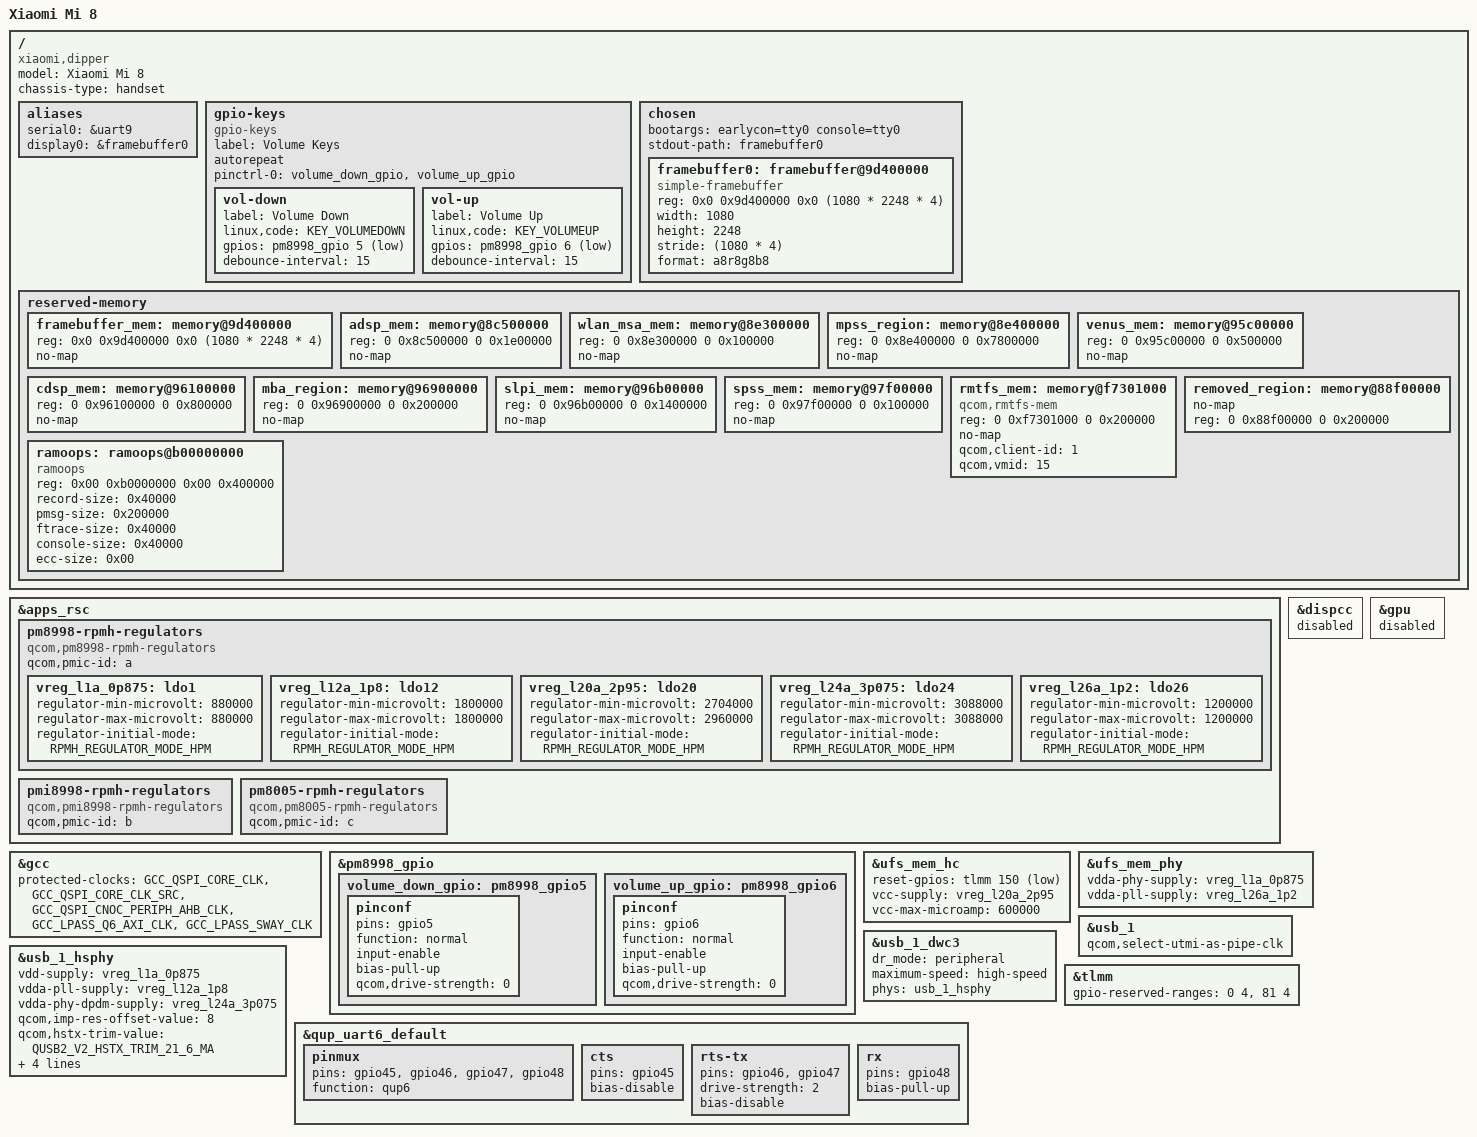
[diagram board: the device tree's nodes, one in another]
// SPDX-License-Identifier: GPL-2.0
/*
 * Copyright (c) 2022, Eralp Çelebi <eralp.celebi.personal@gmail.com>
 *
 */

/dts-v1/;

#include <dt-bindings/input/linux-event-codes.h>
#include <dt-bindings/interrupt-controller/irq.h>
#include <dt-bindings/regulator/qcom,rpmh-regulator.h>
#include <dt-bindings/sound/qcom,q6afe.h>
#include <dt-bindings/sound/qcom,q6asm.h>
#include <dt-bindings/sound/qcom,q6voice.h>

#include "sdm845.dtsi"
#include "pm8998.dtsi"
#include "pmi8998.dtsi"

/*
 * Delete following upstream (sdm845.dtsi) reserved
 * memory mappings which are different in this device.
 */
/delete-node/ &tz_mem;
/delete-node/ &adsp_mem;
/delete-node/ &wlan_msa_mem;
/delete-node/ &mpss_region;
/delete-node/ &venus_mem;
/delete-node/ &cdsp_mem;
/delete-node/ &mba_region;
/delete-node/ &slpi_mem;
/delete-node/ &spss_mem;
/delete-node/ &rmtfs_mem;

/ {
    model = "Xiaomi Mi 8";
    compatible = "xiaomi,dipper", "qcom,sdm845";
    chassis-type = "handset";

    aliases {
		serial0 = &uart9;
		display0 = &framebuffer0;
	};

	gpio-keys {
		compatible = "gpio-keys";
		label = "Volume Keys";
		autorepeat;

		pinctrl-names = "default";
		pinctrl-0 = <&volume_down_gpio &volume_up_gpio>;

		vol-down {
			label = "Volume Down";
			linux,code = <KEY_VOLUMEDOWN>;
			gpios = <&pm8998_gpio 5 GPIO_ACTIVE_LOW>;
			debounce-interval = <15>;
		};

		vol-up {
			label = "Volume Up";
			linux,code = <KEY_VOLUMEUP>;
			gpios = <&pm8998_gpio 6 GPIO_ACTIVE_LOW>;
			debounce-interval = <15>;
		};
	};

    chosen {
        bootargs = "earlycon=tty0 console=tty0";

		#address-cells = <2>;
		#size-cells = <2>;
		ranges;

		stdout-path = "framebuffer0";

        framebuffer0: framebuffer@9d400000 {
            compatible = "simple-framebuffer";
			reg = <0x0 0x9d400000 0x0 (1080 * 2248 * 4)>;
			width = <1080>;
			height = <2248>;
			stride = <(1080 * 4)>;
			format = "a8r8g8b8";
        };
    };

    reserved-memory {
        ranges;

        framebuffer_mem: memory@9d400000 {
			reg = <0x0 0x9d400000 0x0 (1080 * 2248 * 4)>;
			no-map;
		};

		adsp_mem: memory@8c500000 {
			reg = <0 0x8c500000 0 0x1e00000>;
			no-map;
		};

		wlan_msa_mem: memory@8e300000 {
			reg = <0 0x8e300000 0 0x100000>;
			no-map;
		};

		mpss_region: memory@8e400000 {
			reg = <0 0x8e400000 0 0x7800000>;
			no-map;
		};

		venus_mem: memory@95c00000 {
			reg = <0 0x95c00000 0 0x500000>;
			no-map;
		};

		cdsp_mem: memory@96100000 {
			reg = <0 0x96100000 0 0x800000>;
			no-map;
		};

		mba_region: memory@96900000 {
			reg = <0 0x96900000 0 0x200000>;
			no-map;
		};

		slpi_mem: memory@96b00000 {
			reg = <0 0x96b00000 0 0x1400000>;
			no-map;
		};

		spss_mem: memory@97f00000 {
			reg = <0 0x97f00000 0 0x100000>;
			no-map;
		};

		rmtfs_mem: memory@f7301000 {
			compatible = "qcom,rmtfs-mem";
			reg = <0 0xf7301000 0 0x200000>;
			no-map;

			qcom,client-id = <1>;
			qcom,vmid = <15>;
		};

		removed_region: memory@88f00000 {
			no-map;
			reg = <0 0x88f00000 0 0x200000>;
		};


        ramoops: ramoops@b00000000 {
			reg = <0x00 0xb0000000 0x00 0x400000>;
			record-size = <0x40000>;
			pmsg-size = <0x200000>;
			ftrace-size = <0x40000>;
			console-size = <0x40000>;
			compatible = "ramoops";
			ecc-size = <0x00>;
		};
    };
};

&apps_rsc {
	pm8998-rpmh-regulators {
		compatible = "qcom,pm8998-rpmh-regulators";
		qcom,pmic-id = "a";

		vreg_l1a_0p875: ldo1 {
			regulator-min-microvolt = <880000>;
			regulator-max-microvolt = <880000>;
			regulator-initial-mode = <RPMH_REGULATOR_MODE_HPM>;
		};

		vreg_l12a_1p8: ldo12 {
			regulator-min-microvolt = <1800000>;
			regulator-max-microvolt = <1800000>;
			regulator-initial-mode = <RPMH_REGULATOR_MODE_HPM>;
		};

		vreg_l20a_2p95: ldo20 {
			regulator-min-microvolt = <2704000>;
			regulator-max-microvolt = <2960000>;
			regulator-initial-mode = <RPMH_REGULATOR_MODE_HPM>;
		};

		vreg_l24a_3p075: ldo24 {
			regulator-min-microvolt = <3088000>;
			regulator-max-microvolt = <3088000>;
			regulator-initial-mode = <RPMH_REGULATOR_MODE_HPM>;
		};

		vreg_l26a_1p2: ldo26 {
			regulator-min-microvolt = <1200000>;
			regulator-max-microvolt = <1200000>;
			regulator-initial-mode = <RPMH_REGULATOR_MODE_HPM>;
		};
	};

	pmi8998-rpmh-regulators {
		compatible = "qcom,pmi8998-rpmh-regulators";
		qcom,pmic-id = "b";
	};

	pm8005-rpmh-regulators {
		compatible = "qcom,pm8005-rpmh-regulators";
		qcom,pmic-id = "c";
	};
};

&dispcc {
	status = "disabled";
};

&gcc {
	protected-clocks = <GCC_QSPI_CORE_CLK>,
		<GCC_QSPI_CORE_CLK_SRC>,
		<GCC_QSPI_CNOC_PERIPH_AHB_CLK>,
		<GCC_LPASS_Q6_AXI_CLK>,
		<GCC_LPASS_SWAY_CLK>;
};

&gpu {
	status = "disabled";
};

&pm8998_gpio {
	volume_down_gpio: pm8998_gpio5 {
		pinconf {
			pins = "gpio5";
			function = "normal";
			input-enable;
			bias-pull-up;
			qcom,drive-strength = <0>;
		};
	};

	volume_up_gpio: pm8998_gpio6 {
		pinconf {
			pins = "gpio6";
			function = "normal";
			input-enable;
			bias-pull-up;
			qcom,drive-strength = <0>;
		};
	};
};

&ufs_mem_hc {
	status = "okay";

	reset-gpios = <&tlmm 150 GPIO_ACTIVE_LOW>;

	vcc-supply = <&vreg_l20a_2p95>;
	vcc-max-microamp = <600000>;
};

&ufs_mem_phy {
	status = "okay";

	vdda-phy-supply = <&vreg_l1a_0p875>;
	vdda-pll-supply = <&vreg_l26a_1p2>;
};

&usb_1 {
	status = "okay";
	qcom,select-utmi-as-pipe-clk;
};

&usb_1_dwc3 {
	dr_mode = "peripheral";
	maximum-speed = "high-speed";
	phys = <&usb_1_hsphy>;
	phy-names = "usb2-phy";
};

&usb_1_hsphy {
	status = "okay";
	vdd-supply = <&vreg_l1a_0p875>;
	vdda-pll-supply = <&vreg_l12a_1p8>;
	vdda-phy-dpdm-supply = <&vreg_l24a_3p075>;
	qcom,imp-res-offset-value = <8>;
	qcom,hstx-trim-value = <QUSB2_V2_HSTX_TRIM_21_6_MA>;
	qcom,preemphasis-level = <QUSB2_V2_PREEMPHASIS_5_PERCENT>;
	qcom,preemphasis-width = <QUSB2_V2_PREEMPHASIS_WIDTH_HALF_BIT>;
};

&tlmm {
	gpio-reserved-ranges = <0 4>, <81 4>;
};

&qup_uart6_default {
	pinmux {
		pins = "gpio45", "gpio46", "gpio47", "gpio48";
		function = "qup6";
	};

	cts {
		pins = "gpio45";
		bias-disable;
	};

	rts-tx {
		pins = "gpio46", "gpio47";
		drive-strength = <2>;
		bias-disable;
	};

	rx {
		pins = "gpio48";
		bias-pull-up;
	};
};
